VERSION "1"

NS_ :

BS_:

BU_: Ecu1 Ecu2

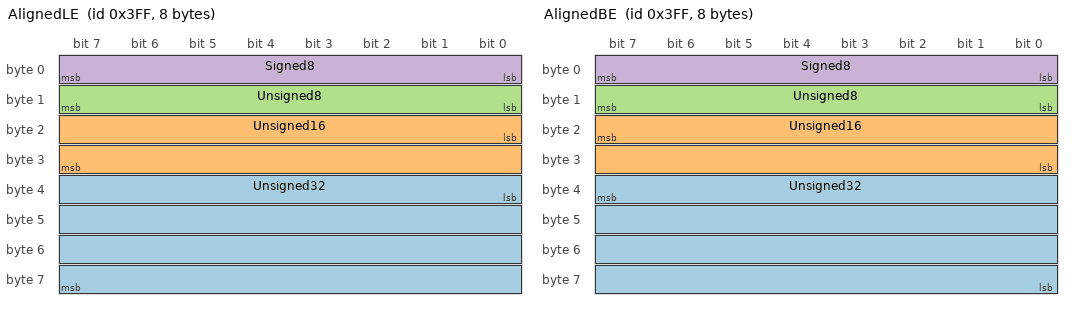
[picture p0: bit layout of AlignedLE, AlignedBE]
BO_ 1023 AlignedLE: 8 Ecu1
 SG_ Unsigned32 : 32|32@1+ (1,0) [0|0] "" Vector__XXX
 SG_ Unsigned16 : 16|16@1+ (1,0) [0|0] "" Vector__XXX
 SG_ Unsigned8 : 8|8@1+ (1,0) [0|0] "" Vector__XXX
 SG_ Signed8 : 0|8@1- (1,0) [0|0] "" Vector__XXX

BO_ 1023 AlignedBE: 8 Ecu1
 SG_ Unsigned32 : 39|32@0+ (1,0) [0|0] "" Vector__XXX
 SG_ Unsigned16 : 23|16@0+ (1,0) [0|0] "" Vector__XXX
 SG_ Unsigned8 : 15|8@0+ (1,0) [0|0] "" Vector__XXX
 SG_ Signed8 : 7|8@0- (1,0) [0|0] "" Vector__XXX

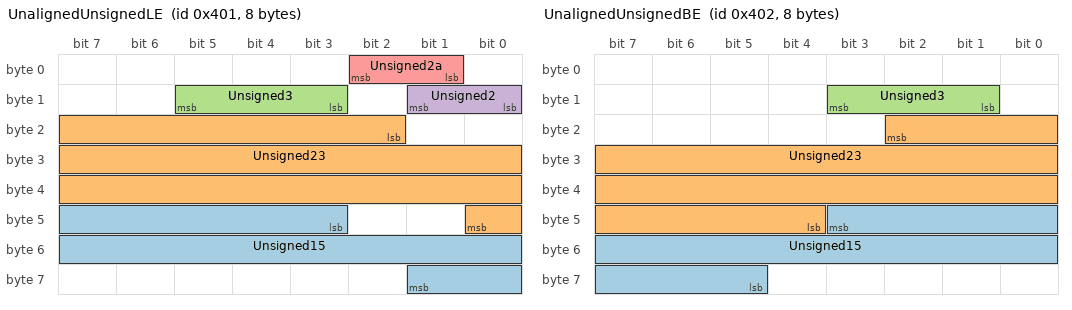
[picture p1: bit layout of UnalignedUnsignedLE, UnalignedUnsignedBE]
BO_ 1025 UnalignedUnsignedLE: 8 Ecu1
 SG_ Unsigned15 : 43|15@1+ (1,0) [0|0] "" Vector__XXX
 SG_ Unsigned23 : 18|23@1+ (1,0) [0|0] "" Vector__XXX
 SG_ Unsigned3 : 11|3@1+ (1,0) [0|0] "" Vector__XXX
 SG_ Unsigned2 : 8|2@1+ (1,0) [0|0] "" Vector__XXX
 SG_ Unsigned2a : 1|2@1+ (1,0) [0|0] "" Vector__XXX

BO_ 1026 UnalignedUnsignedBE: 8 Ecu1
 SG_ Unsigned15 : 43|15@0+ (1,0) [0|0] "" Vector__XXX
 SG_ Unsigned23 : 18|23@0+ (1,0) [0|0] "" Vector__XXX
 SG_ Unsigned3 : 11|3@0+ (1,0) [0|0] "" Vector__XXX

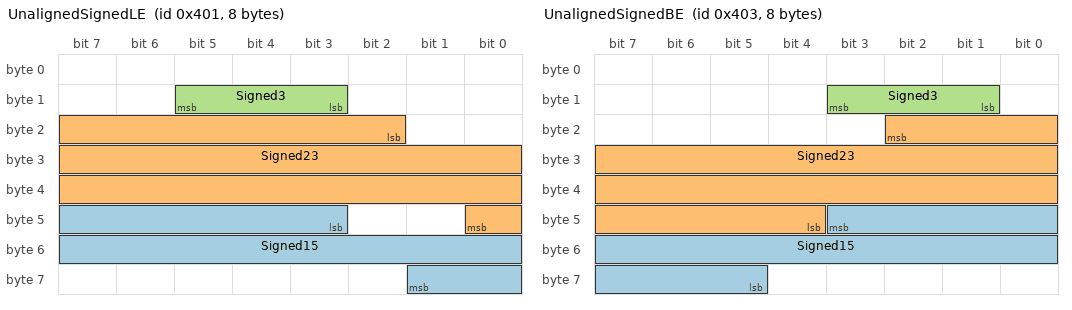
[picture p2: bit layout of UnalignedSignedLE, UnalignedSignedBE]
BO_ 1025 UnalignedSignedLE: 8 Ecu1
 SG_ Signed15 : 43|15@1- (1,0) [0|0] "" Vector__XXX
 SG_ Signed23 : 18|23@1- (1,0) [0|0] "" Vector__XXX
 SG_ Signed3 : 11|3@1- (1,0) [0|0] "" Vector__XXX

BO_ 1027 UnalignedSignedBE: 8 Ecu1
 SG_ Signed15 : 43|15@0- (1,0) [0|0] "" Vector__XXX
 SG_ Signed23 : 18|23@0- (1,0) [0|0] "" Vector__XXX
 SG_ Signed3 : 11|3@0- (1,0) [0|0] "" Vector__XXX

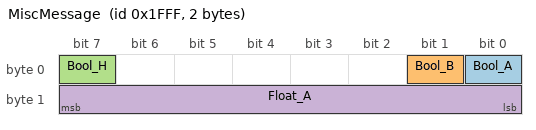
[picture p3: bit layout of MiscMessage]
BO_ 8191 MiscMessage: 2 Ecu2
 SG_ Bool_A : 0|1@1+ (1,0) [0|1] "" Vector__XXX
 SG_ Bool_B : 1|1@1+ (1,0) [0|1] "" Vector__XXX
 SG_ Bool_H : 7|1@1+ (1,0) [0|1] "" Vector__XXX
 SG_ Float_A : 8|8@1+ (0.5,0.25) [0|0] "" Vector__XXX

BO_ 64 SixtyFourBitLE: 8 Ecu2
 SG_ SixtyFour : 0|64@1+ (1,0) [0|0] "" Vector_XXX

BO_ 65 SixtyFourBitBE: 8 Ecu2
 SG_ SixtyFour : 7|64@0+ (1,0) [0|0] "" Vector_XXX

BO_ 66 SixtyFourBitSigned: 8 Ecu2
 SG_ SixtyFour : 0|64@1- (1,0) [0|0] "" Vector_XXX

BO_ 128 GroupData1: 8 Ecu1
 SG_ ValueA : 0|32@1+ (1,0) [0|0] "" Vector__XXX
 SG_ ValueB : 32|32@1+ (1,0) [0|0] "" Vector__XXX

BO_ 129 GroupData2: 8 Ecu1
 SG_ ValueA : 0|32@1+ (1,0) [0|0] "" Vector__XXX
 SG_ ValueB : 32|32@1+ (1,0) [0|0] "" Vector__XXX

BO_ 130 GroupData3: 8 Ecu1
 SG_ ValueA : 0|32@1+ (1,0) [0|0] "" Vector__XXX
 SG_ ValueB : 32|32@1+ (1,0) [0|0] "" Vector__XXX

BO_ 2148676694 Extended1: 8 Ecu1
 SG_ DataA : 0|32@1+ (1,0) [0|0] "" Vector__XXX

BA_DEF_DEF_  "GenMsgCycleTime" 0;

BA_ "GenMsgCycleTime" BO_ 8191 100;
BA_ "GenMsgCycleTime" BO_ 66 2000;

VAL_ 8191 Bool_A 1 "On" 0 "Off" ;
VAL_ 8191 Float_A 31415 "Pi" 27182 "e" ;
VAL_ 1026 Unsigned15 33 "Thirty-three" 37 "Thirty-seven" 17283 "Test";
